# nrf54h20_engb_sysctrl register map
Vendor: Nordic Semiconductor; Series: nRF54h; File version: 1
Registers are 32-bit, read-write, reset 0x0 unless marked. A register's access mark holds for its fields unless they carry their own. Offsets are from the block's base; [hi:lo] are bit positions; lines under a group give offsets from that group; 'fields as' and 'values as' point back to an identical list.

## LFLPRC — LFLPRC peripheral
Base 0x5F952000
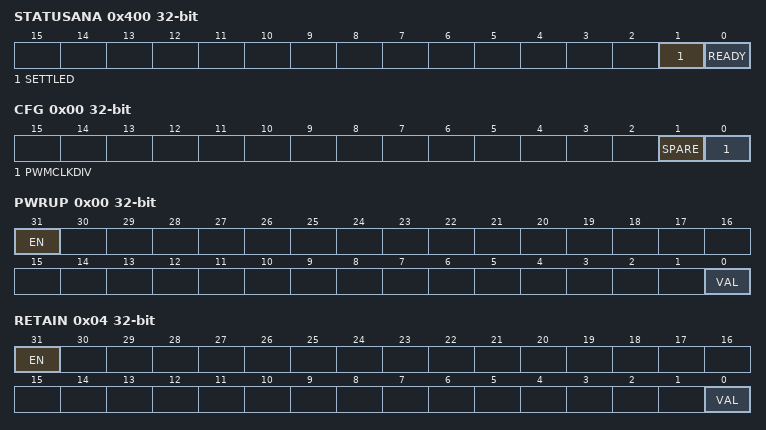
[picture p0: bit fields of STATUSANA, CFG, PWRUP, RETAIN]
0x400 STATUSANA ro — Status of analog module output signals
  [1] SETTLED — Current value of the SETTLED signal from the analog module
  [0] READY — Current value of the READY signal from the analog module
0x410 CONFIG group — Unspecified
  0x00 CFG — Oscillator configuration
    [1] SPARE — Spare bit, for future use
    [0] PWMCLKDIV — PWM input clock divider ratio
      0=Div2 (PWM input clock divided by 2); 1=Div1 (PWM input clock divided by 1)
0x440 TRIM group — Unspecified
  0x00 VSUP — Internal reference current generator trim
    [3:0] VALUE — Trim value
  0x04 RCOARSE — Coarse frequency static R trimming
    [5:0] VALUE — Coarse frequency trimming of R in RC network
  0x08 RFINE — Fine frequency static R trimming
    [5:0] VALUE — Fine frequency trimming of R in RC network
  0x0C PWMFINE — Fine frequency dynamic PWM trim
    [3:0] VALUE — Duty cycle of PWM fine frequency LSB resistor
0x480 MIRROR reset 0x1 — Enable LOCK for mirrored registers
  [0] LOCK — Lock for mirrored registers
    0=Disabled (Lock disabled); 1=Enabled (Lock enabled)
0x500 OVERRIDE group — Unspecified
  0x00 PWRUP — Override the PWRUP signal to the analog module
    [31] EN — Enable the override
      0=Disabled (Override is disabled); 1=Enabled (Override is enabled)
    [0] VAL — Override value for the signal
  0x04 RETAIN — Override the RETAIN signal to the analog module
    fields as OVERRIDE.PWRUP
0x600 DFT group — Unspecified
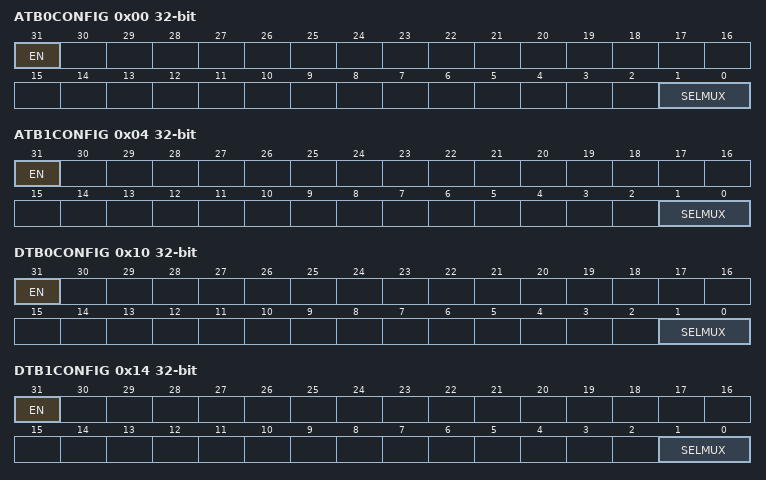
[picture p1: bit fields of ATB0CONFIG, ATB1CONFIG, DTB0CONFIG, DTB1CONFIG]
  0x00 ATB0CONFIG — Analog Test Bus 0 (ATB0) configuration
    [31] EN — Enable the analog test bus
      0=Disabled (Analog test bus is disabled); 1=Enabled (Analog test bus is enabled)
    [1:0] SELMUX — Select multiplexer for ATB0
      0=VddInt1v8 (Connect ATB0 for external forcing of internal 1V8 supply); 1=Spare0 (None selected, HiZ); 2=VddInt0v8 (Connect ATB0 for external forcing of internal 0V8 supply); 3=Spare1 (None selected, HiZ)
  0x04 ATB1CONFIG — Analog Test Bus 1 (ATB1) configuration
    [31] EN — Enable the analog test bus
      values as DFT.ATB0CONFIG.EN
    [1:0] SELMUX — Select multiplexer for ATB1
      0=VddSw1v8 (Sense voltage from charge pump); 1=Vreg0v5 (Sense voltage from source follower); 2=Spare0 (None selected, HiZ); 3=Spare1 (None selected, HiZ)
  0x10 DTB0CONFIG — Digital Test Bus 0 (DTB0) configuration
    [31] EN — Enable the digital test bus
      0=Disabled (Digital test bus is disabled); 1=Enabled (Digital test bus is enabled)
    [1:0] SELMUX — Select multiplexer for DTB0
      0=Ready signal; 1=AfsmS0 (LSB of internal state); 2=Settled signal; 3=Spare0 (None selected, logic 0)
  0x14 DTB1CONFIG — Digital Test Bus 1 (DTB1) configuration
    [31] EN — Enable the digital test bus
      values as DFT.DTB0CONFIG.EN
    [1:0] SELMUX — Select multiplexer for DTB1
      0=Spare0 (None selected, logic 0); 1=AfsmS1 (MSB of internal state); 2=Pwm (Fine trim PWM signal); 3=Spare1 (None selected, logic 0)
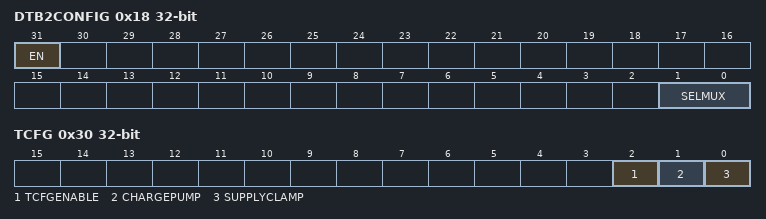
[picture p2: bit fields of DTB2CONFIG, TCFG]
  0x18 DTB2CONFIG — Digital Test Bus 2 (DTB2) configuration
    [31] EN — Enable the digital test bus
      values as DFT.DTB0CONFIG.EN
    [1:0] SELMUX — Select multiplexer for DTB2
      0=OscOut (Internal oscillator output); 1=CntReady (Startup counter overflow); 2=IrefReady (Reference current generator ready signal); 3=Spare0 (None selected, logic 0)
  0x1C DTB3CONFIG — Digital Test Bus 3 (DTB3) configuration
    [27] PWRUPDELTEST — Enable the PWRUP delay test circuit
      0=Disabled (PWRUP delay test circuit is disabled); 1=Enabled (PWRUP delay test circuit is enabled)
  0x30 TCFG — Test mode configuration
    [all] fields
      0=Disabled (Unspecified); 1=Enabled (Unspecified)
    [2] TCFGENABLE — Enable TCFG control and force settled signal high
    [1] CHARGEPUMP — Chargepump control
    [0] SUPPLYCLAMP — Local supply clamp control
